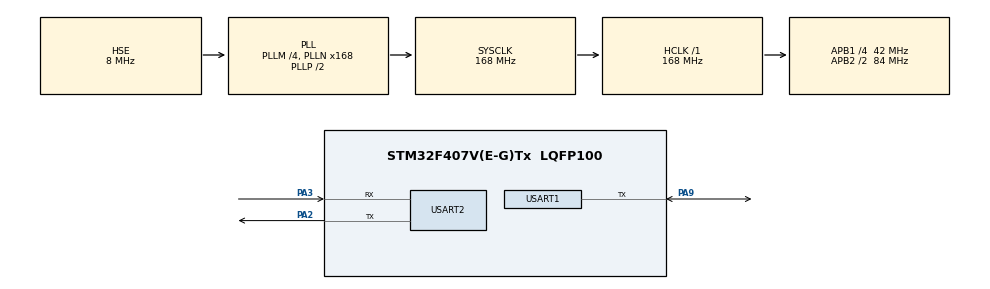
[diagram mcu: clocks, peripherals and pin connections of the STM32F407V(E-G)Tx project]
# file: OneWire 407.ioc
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Dma.Request0=USART1_RX
Dma.Request1=USART1_TX
Dma.USART1_RX.0.Direction=DMA_PERIPH_TO_MEMORY
Dma.USART1_RX.0.FIFOMode=DMA_FIFOMODE_DISABLE
Dma.USART1_RX.0.Instance=DMA2_Stream2
Dma.USART1_RX.0.MemDataAlignment=DMA_MDATAALIGN_BYTE
Dma.USART1_RX.0.MemInc=DMA_MINC_ENABLE
Dma.USART1_RX.0.Mode=DMA_NORMAL
Dma.USART1_RX.0.PeriphDataAlignment=DMA_PDATAALIGN_BYTE
Dma.USART1_RX.0.PeriphInc=DMA_PINC_DISABLE
Dma.USART1_RX.0.Priority=DMA_PRIORITY_LOW
Dma.USART1_TX.1.Direction=DMA_MEMORY_TO_PERIPH
Dma.USART1_TX.1.FIFOMode=DMA_FIFOMODE_DISABLE
Dma.USART1_TX.1.Instance=DMA2_Stream7
Dma.USART1_TX.1.MemDataAlignment=DMA_MDATAALIGN_BYTE
Dma.USART1_TX.1.MemInc=DMA_MINC_ENABLE
Dma.USART1_TX.1.Mode=DMA_NORMAL
Dma.USART1_TX.1.PeriphDataAlignment=DMA_PDATAALIGN_BYTE
Dma.USART1_TX.1.PeriphInc=DMA_PINC_DISABLE
Dma.USART1_TX.1.Priority=DMA_PRIORITY_LOW
Mcu.Family=STM32F4
Mcu.Name=STM32F407V(E-G)Tx
Mcu.Package=LQFP100
NVIC.DMA2_Stream2_IRQn=true\:0\:0\:false\:false\:true\:false\:true
NVIC.DMA2_Stream7_IRQn=true\:0\:0\:false\:false\:true\:false\:true
NVIC.PriorityGroup=NVIC_PRIORITYGROUP_4
NVIC.USART1_IRQn=true\:0\:0\:false\:false\:true\:true\:true
PA13.Mode=Serial_Wire
PA13.Signal=SYS_JTMS-SWDIO
PA14.Mode=Serial_Wire
PA14.Signal=SYS_JTCK-SWCLK
PA2.Mode=Asynchronous
PA2.Signal=USART2_TX
PA3.Mode=Asynchronous
PA3.Signal=USART2_RX
PA9.Mode=Half_duplex(single_wire_mode)
PA9.Signal=USART1_TX
PH0-OSC_IN.Mode=HSE-External-Oscillator
PH0-OSC_IN.Signal=RCC_OSC_IN
PH1-OSC_OUT.Mode=HSE-External-Oscillator
PH1-OSC_OUT.Signal=RCC_OSC_OUT
ProjectManager.HeapSize=0x200
ProjectManager.StackSize=0x400
ProjectManager.TargetToolchain=STM32CubeIDE
RCC.48MHZClocksFreq_Value=84000000
RCC.AHBFreq_Value=168000000
RCC.APB1CLKDivider=RCC_HCLK_DIV4
RCC.APB1Freq_Value=42000000
RCC.APB1TimFreq_Value=84000000
RCC.APB2CLKDivider=RCC_HCLK_DIV2
RCC.APB2Freq_Value=84000000
RCC.APB2TimFreq_Value=168000000
RCC.CortexFreq_Value=168000000
RCC.HCLKFreq_Value=168000000
RCC.HSE_VALUE=8000000
RCC.HSI_VALUE=16000000
RCC.LSE_VALUE=32768
RCC.PLLM=4
RCC.PLLN=168
RCC.PLLSourceVirtual=RCC_PLLSOURCE_HSE
RCC.SYSCLKFreq_VALUE=168000000
RCC.SYSCLKSource=RCC_SYSCLKSOURCE_PLLCLK
RCC.VCOOutputFreq_Value=336000000
USART1.VirtualMode=VM_ASYNC
USART2.VirtualMode=VM_ASYNC
board=custom

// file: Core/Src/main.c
/* USER CODE BEGIN Header */
/**
 ******************************************************************************
 * @file           : main.c
 * @brief          : Main program body
 ******************************************************************************
 * @attention
 *
 * <h2><center>&copy; Copyright (c) 2021 STMicroelectronics.
 * All rights reserved.</center></h2>
 *
 * This software component is licensed by ST under BSD 3-Clause license,
 * the "License"; You may not use this file except in compliance with the
 * License. You may obtain a copy of the License at:
 *                        opensource.org/licenses/BSD-3-Clause
 *
 ******************************************************************************
 */
/* USER CODE END Header */
#include "main.h"

/* USER CODE BEGIN Includes */
#include "stdio.h"
#include "OneWire.h"
#include "DallasTemperature.h"
//#include <stdio.h> /* для printf */
/* USER CODE END Includes */

UART_HandleTypeDef huart1;
UART_HandleTypeDef huart2;
DMA_HandleTypeDef hdma_usart1_rx;
DMA_HandleTypeDef hdma_usart1_tx;

/* USER CODE BEGIN PV */
OneWire_HandleTypeDef ow;
DallasTemperature_HandleTypeDef dt;
/* USER CODE END PV */

void SystemClock_Config(void);
static void MX_GPIO_Init(void);
static void MX_USART2_UART_Init(void);
static void MX_DMA_Init(void);
static void MX_USART1_UART_Init(void);

/* USER CODE BEGIN 0 */
// function to print a device address
void printAddress(CurrentDeviceAddress deviceAddress) {
	for (uint8_t i = 0; i < 6; i++) {  // Указал количество датчиков 7шт.
		printf("0x%02X ", deviceAddress[i]);
		HAL_Delay(50); //Сделал паузу.
	}
}
/* USER CODE END 0 */

int main(void) {

	/* MCU Configuration--------------------------------------------------------*/

	/* Reset of all peripherals, Initializes the Flash interface and the Systick. */
	HAL_Init();

	/* Configure the system clock */
	SystemClock_Config();

	/* Initialize all configured peripherals */
	MX_GPIO_Init();
	MX_USART2_UART_Init();
	MX_DMA_Init();
	MX_USART1_UART_Init();
	/* USER CODE BEGIN 2 */

	//printf("[%8lu] Debug UART1 is OK!\r\n", HAL_GetTick());
	char msg[100];
	sprintf(msg, "[%8lu] Debug UART1 is OK!\r\n", HAL_GetTick());
	HAL_UART_Transmit(&huart2, (uint8_t*) msg, strlen(msg), 500);

	OW_Begin(&ow, &huart1);
	if (OW_Reset(&ow) == OW_OK) {
		//printf("[%8lu] OneWire devices are present :)\r\n", HAL_GetTick());
		sprintf(msg, "[%8lu] OneWire devices are present :)\r\n",HAL_GetTick());
		HAL_UART_Transmit(&huart2, (uint8_t*) msg, strlen(msg), 500);
	} else {
		//printf("[%8lu] OneWire no devices :(\r\n", HAL_GetTick());
		sprintf(msg, "[%8lu] OneWire no devices :\r\n", HAL_GetTick());
		HAL_UART_Transmit(&huart2, (uint8_t*) msg, strlen(msg), 500);
	}
	DT_SetOneWire(&dt, &ow);
	// arrays to hold device address
	CurrentDeviceAddress insideThermometer;
	// locate devices on the bus
	//printf("[%8lu] Locating devices...", HAL_GetTick());
	sprintf(msg, "[%8lu] Locating devices...", HAL_GetTick());
	HAL_UART_Transmit(&huart2, (uint8_t*) msg, strlen(msg), 500);
	DT_Begin(&dt);
	//printf("[%8lu] Found %d devices.\r\n", HAL_GetTick(), DT_GetDeviceCount(&dt));
	sprintf(msg, "[%8lu] Found %d devices.\r\n", HAL_GetTick(),DT_GetDeviceCount(&dt));
	HAL_UART_Transmit(&huart2, (uint8_t*) msg, strlen(msg), 500);
	if (!DT_GetAddress(&dt, insideThermometer, 0)) {
		//printf("[%8lu] Unable to find address for Device 0\r\n", HAL_GetTick());
		sprintf(msg, "[%8lu] Unable to find address for Device 0\r\n",HAL_GetTick());
		HAL_UART_Transmit(&huart2, (uint8_t*) msg, strlen(msg), 500);
		//printf("[%8lu] Device 0 Address: ", HAL_GetTick());
		sprintf(msg, "[%8lu] Device 0 Address: \r\n", HAL_GetTick());
		HAL_UART_Transmit(&huart2, (uint8_t*) msg, strlen(msg), 500);
		printAddress(insideThermometer);
		printf("\r\n");
	}
	// set the resolution to 12 bit (Each Dallas/Maxim device is capable of several different resolutions)
	DT_SetResolution(&dt, insideThermometer, 12, true);
	//printf("[%8lu] Device 0 Resolution: %d\r\n", HAL_GetTick(), DT_GetResolution(&dt, insideThermometer));
	sprintf(msg, "[%8lu] Device 0 Resolution: %d\r\n", HAL_GetTick(),DT_GetResolution(&dt, insideThermometer));
	HAL_UART_Transmit(&huart2, (uint8_t*) msg, strlen(msg), 500);

	if (!DT_GetAddress(&dt, insideThermometer, 1)) {
		//printf("[%8lu] Unable to find address for Device 1\r\n", HAL_GetTick());
		sprintf(msg, "[%8lu] Unable to find address for Device 1\r\n",HAL_GetTick());
		HAL_UART_Transmit(&huart2, (uint8_t*) msg, strlen(msg), 500);
		//printf("[%8lu] Device 1 Address: ", HAL_GetTick());
		sprintf(msg, "[%8lu] Device 1 Address: \r\n", HAL_GetTick());
		HAL_UART_Transmit(&huart2, (uint8_t*) msg, strlen(msg), 500);
		printAddress(insideThermometer);
		printf("\r\n");
		// set the resolution to 12 bit (Each Dallas/Maxim device is capable of several different resolutions)
		DT_SetResolution(&dt, insideThermometer, 12, true);
		//printf("[%8lu] Device 1 Resolution: %d\r\n", HAL_GetTick(), DT_GetResolution(&dt, insideThermometer));
		sprintf(msg, "[%8lu] Device 1 Resolution: %d\r\n", HAL_GetTick(),DT_GetResolution(&dt, insideThermometer));
		HAL_UART_Transmit(&huart2, (uint8_t*) msg, strlen(msg), 500);
	}
	/* USER CODE END 2 */

	/* Infinite loop */
	while (1) {

		/* USER CODE BEGIN 3 */
		// call DT_RequestTemperatures(&dt) to issue a global temperature
		// request to all devices on the bus
		//printf("[%8lu] Requesting temperatures...", HAL_GetTick());
		sprintf(msg, "[%8lu] Requesting temperatures...", HAL_GetTick());
		HAL_UART_Transmit(&huart2, (uint8_t*) msg, strlen(msg), 500);
		DT_RequestTemperatures(&dt); // Send the command to get temperatures
		//printf("\r\n[%8lu] DONE\r\n", HAL_GetTick());
		sprintf(msg, "\r\n[%8lu] DONE\r\n", HAL_GetTick());
		HAL_UART_Transmit(&huart2, (uint8_t*) msg, strlen(msg), 500);
		// After we got the temperatures, we can print them here.
		// We use the function ByIndex, and as an example get the temperature from the first sensor only.
		//printf("[%8lu] Temperature for the device 1 (index 0) is: %.2f\r\n", HAL_GetTick(), DT_GetTempCByIndex(&dt, 0));
		sprintf(msg,"[%8lu] Temperature for the device 1 (index 0) is: %.2f\r\n",HAL_GetTick(), DT_GetTempCByIndex(&dt, 0));
		HAL_UART_Transmit(&huart2, (uint8_t*) msg, strlen(msg), 500);
		//printf("[%8lu] Temperature for the device 2 (index 1) is: %.2f\r\n", HAL_GetTick(), DT_GetTempCByIndex(&dt, 1));
		sprintf(msg,"[%8lu] Temperature for the device 2 (index 1) is: %.2f\r\n",HAL_GetTick(), DT_GetTempCByIndex(&dt, 1));
		HAL_UART_Transmit(&huart2, (uint8_t*) msg, strlen(msg), 500);
		//printf("[%8lu] Temperature for the device 3 (index 2) is: %.2f\r\n", HAL_GetTick(), DT_GetTempCByIndex(&dt, 2));
		sprintf(msg,"[%8lu] Temperature for the device 3 (index 2) is: %.2f\r\n",HAL_GetTick(), DT_GetTempCByIndex(&dt, 2));
		HAL_UART_Transmit(&huart2, (uint8_t*) msg, strlen(msg), 500);
		//printf("[%8lu] Temperature for the device 4 (index 3) is: %.2f\r\n", HAL_GetTick(), DT_GetTempCByIndex(&dt, 3));
		sprintf(msg,"[%8lu] Temperature for the device 4 (index 3) is: %.2f\r\n",HAL_GetTick(), DT_GetTempCByIndex(&dt, 3));
		HAL_UART_Transmit(&huart2, (uint8_t*) msg, strlen(msg), 500);
		//printf("[%8lu] Temperature for the device 5 (index 4) is: %.2f\r\n", HAL_GetTick(), DT_GetTempCByIndex(&dt, 4));
		sprintf(msg,"[%8lu] Temperature for the device 5 (index 4) is: %.2f\r\n",HAL_GetTick(), DT_GetTempCByIndex(&dt, 4));
		HAL_UART_Transmit(&huart2, (uint8_t*) msg, strlen(msg), 500);
		//printf("[%8lu] Temperature for the device 6 (index 5) is: %.2f\r\n", HAL_GetTick(), DT_GetTempCByIndex(&dt, 5));
		sprintf(msg,"[%8lu] Temperature for the device 6 (index 5) is: %.2f\r\n",HAL_GetTick(), DT_GetTempCByIndex(&dt, 5));
		HAL_UART_Transmit(&huart2, (uint8_t*) msg, strlen(msg), 500);
		//printf("[%8lu] Temperature for the device 7 (index 6) is: %.2f\r\n", HAL_GetTick(), DT_GetTempCByIndex(&dt, 6));
		sprintf(msg,"[%8lu] Temperature for the device 7 (index 6) is: %.2f\r\n",HAL_GetTick(), DT_GetTempCByIndex(&dt, 6));
		HAL_UART_Transmit(&huart2, (uint8_t*) msg, strlen(msg), 500);

		HAL_Delay(2000);
	}
	/* USER CODE END 3 */
}

void SystemClock_Config(void) {
	RCC_OscInitTypeDef RCC_OscInitStruct = { 0 };
	RCC_ClkInitTypeDef RCC_ClkInitStruct = { 0 };

	/** Configure the main internal regulator output voltage
	 */
	__HAL_RCC_PWR_CLK_ENABLE();
	__HAL_PWR_VOLTAGESCALING_CONFIG(PWR_REGULATOR_VOLTAGE_SCALE1);
	/** Initializes the RCC Oscillators according to the specified parameters
	 * in the RCC_OscInitTypeDef structure.
	 */
	RCC_OscInitStruct.OscillatorType = RCC_OSCILLATORTYPE_HSE;
	RCC_OscInitStruct.HSEState = RCC_HSE_ON;
	RCC_OscInitStruct.PLL.PLLState = RCC_PLL_ON;
	RCC_OscInitStruct.PLL.PLLSource = RCC_PLLSOURCE_HSE;
	RCC_OscInitStruct.PLL.PLLM = 4;
	RCC_OscInitStruct.PLL.PLLN = 168;
	RCC_OscInitStruct.PLL.PLLP = RCC_PLLP_DIV2;
	RCC_OscInitStruct.PLL.PLLQ = 4;
	if (HAL_RCC_OscConfig(&RCC_OscInitStruct) != HAL_OK) {
		Error_Handler();
	}
	/** Initializes the CPU, AHB and APB buses clocks
	 */
	RCC_ClkInitStruct.ClockType = RCC_CLOCKTYPE_HCLK | RCC_CLOCKTYPE_SYSCLK
			| RCC_CLOCKTYPE_PCLK1 | RCC_CLOCKTYPE_PCLK2;
	RCC_ClkInitStruct.SYSCLKSource = RCC_SYSCLKSOURCE_PLLCLK;
	RCC_ClkInitStruct.AHBCLKDivider = RCC_SYSCLK_DIV1;
	RCC_ClkInitStruct.APB1CLKDivider = RCC_HCLK_DIV4;
	RCC_ClkInitStruct.APB2CLKDivider = RCC_HCLK_DIV2;

	if (HAL_RCC_ClockConfig(&RCC_ClkInitStruct, FLASH_LATENCY_5) != HAL_OK) {
		Error_Handler();
	}
}

static void MX_USART1_UART_Init(void) {

	huart1.Instance = USART1;
	huart1.Init.BaudRate = 115200;
	huart1.Init.WordLength = UART_WORDLENGTH_8B;
	huart1.Init.StopBits = UART_STOPBITS_1;
	huart1.Init.Parity = UART_PARITY_NONE;
	huart1.Init.Mode = UART_MODE_TX_RX;
	huart1.Init.HwFlowCtl = UART_HWCONTROL_NONE;
	huart1.Init.OverSampling = UART_OVERSAMPLING_16;
	if (HAL_HalfDuplex_Init(&huart1) != HAL_OK) {
		Error_Handler();
	}

}

static void MX_USART2_UART_Init(void) {

	huart2.Instance = USART2;
	huart2.Init.BaudRate = 115200;
	huart2.Init.WordLength = UART_WORDLENGTH_8B;
	huart2.Init.StopBits = UART_STOPBITS_1;
	huart2.Init.Parity = UART_PARITY_NONE;
	huart2.Init.Mode = UART_MODE_TX_RX;
	huart2.Init.HwFlowCtl = UART_HWCONTROL_NONE;
	huart2.Init.OverSampling = UART_OVERSAMPLING_16;
	if (HAL_UART_Init(&huart2) != HAL_OK) {
		Error_Handler();
	}

}

static void MX_DMA_Init(void) {

	/* DMA controller clock enable */
	__HAL_RCC_DMA2_CLK_ENABLE();

	/* DMA interrupt init */
	/* DMA2_Stream2_IRQn interrupt configuration */
	HAL_NVIC_SetPriority(DMA2_Stream2_IRQn, 0, 0);
	HAL_NVIC_EnableIRQ(DMA2_Stream2_IRQn);
	/* DMA2_Stream7_IRQn interrupt configuration */
	HAL_NVIC_SetPriority(DMA2_Stream7_IRQn, 0, 0);
	HAL_NVIC_EnableIRQ(DMA2_Stream7_IRQn);

}

static void MX_GPIO_Init(void) {

	/* GPIO Ports Clock Enable */
	__HAL_RCC_GPIOH_CLK_ENABLE();
	__HAL_RCC_GPIOA_CLK_ENABLE();

}

void Error_Handler(void) {
	__disable_irq();
	while (1) {
	}
}

/************************ (C) COPYRIGHT STMicroelectronics *****END OF FILE****/
